# STM32G071 register map
File version: 2.1
CPU: CM0 r0p1, little endian, MPU, no FPU, 4 interrupt priority bits
Registers are 32-bit, read-write, reset 0x0 unless marked. A register's access mark holds for its fields unless they carry their own. Offsets are from the block's base; [hi:lo] are bit positions.

## TIM16 — General purpose timers
Base 0x40014400
Same registers: TIM17 0x40014800
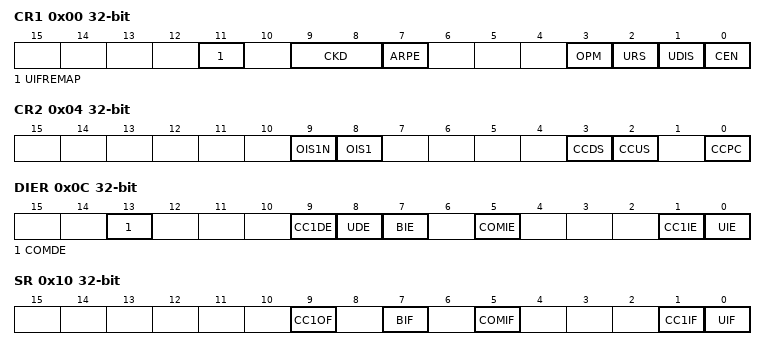
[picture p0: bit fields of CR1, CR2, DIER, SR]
0x00 CR1 — control register 1
  [11] UIFREMAP — UIF status bit remapping
  [9:8] CKD — Clock division
  [7] ARPE — Auto-reload preload enable
  [3] OPM — One-pulse mode
  [2] URS — Update request source
  [1] UDIS — Update disable
  [0] CEN — Counter enable
0x04 CR2 — control register 2
  [9] OIS1N — Output Idle state 1
  [8] OIS1 — Output Idle state 1
  [3] CCDS — Capture/compare DMA selection
  [2] CCUS — Capture/compare control update selection
  [0] CCPC — Capture/compare preloaded control
0x0C DIER — DMA/Interrupt enable register
  [13] COMDE — COM DMA request enable
  [9] CC1DE — Capture/Compare 1 DMA request enable
  [8] UDE — Update DMA request enable
  [7] BIE — Break interrupt enable
  [5] COMIE — COM interrupt enable
  [1] CC1IE — Capture/Compare 1 interrupt enable
  [0] UIE — Update interrupt enable
0x10 SR — status register
  [9] CC1OF — Capture/Compare 1 overcapture flag
  [7] BIF — Break interrupt flag
  [5] COMIF — COM interrupt flag
  [1] CC1IF — Capture/compare 1 interrupt flag
  [0] UIF — Update interrupt flag
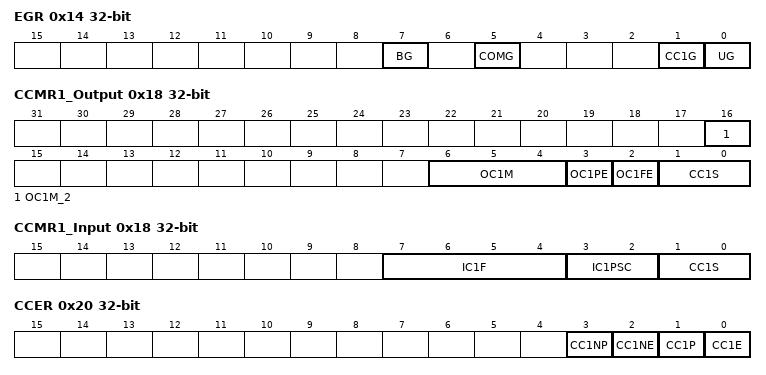
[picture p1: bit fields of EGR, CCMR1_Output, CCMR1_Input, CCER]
0x14 EGR wo — event generation register
  [7] BG — Break generation
  [5] COMG — Capture/Compare control update generation
  [1] CC1G — Capture/compare 1 generation
  [0] UG — Update generation
0x18 CCMR1_Output — capture/compare mode register (output mode)
  [16] OC1M_2 — Output Compare 1 mode
  [6:4] OC1M — Output Compare 1 mode
  [3] OC1PE — Output Compare 1 preload enable
  [2] OC1FE — Output Compare 1 fast enable
  [1:0] CC1S — Capture/Compare 1 selection
0x18 CCMR1_Input (alternate view of CCMR1_Output) — capture/compare mode register 1 (input mode)
  [7:4] IC1F — Input capture 1 filter
  [3:2] IC1PSC — Input capture 1 prescaler
  [1:0] CC1S — Capture/Compare 1 selection
0x20 CCER — capture/compare enable register
  [3] CC1NP — Capture/Compare 1 output Polarity
  [2] CC1NE — Capture/Compare 1 complementary output enable
  [1] CC1P — Capture/Compare 1 output Polarity
  [0] CC1E — Capture/Compare 1 output enable
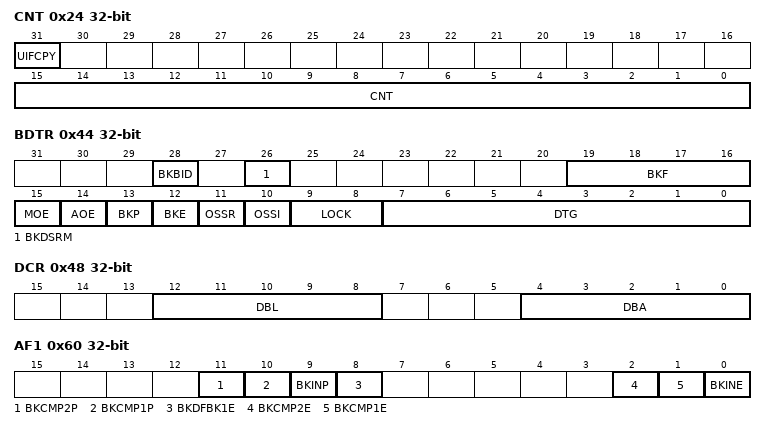
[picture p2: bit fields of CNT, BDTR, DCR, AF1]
0x24 CNT access per field — counter
  [31] UIFCPY ro — UIF Copy
  [15:0] CNT rw — counter value
0x28 PSC — prescaler
  [15:0] PSC — Prescaler value
0x2C ARR — auto-reload register
  [15:0] ARR — Auto-reload value
0x30 RCR — repetition counter register
  [7:0] REP — Repetition counter value
0x34 CCR1 — capture/compare register 1
  [15:0] CCR1 — Capture/Compare 1 value
0x44 BDTR — break and dead-time register
  [28] BKBID — Break Bidirectional
  [26] BKDSRM — Break Disarm
  [19:16] BKF — Break filter
  [15] MOE — Main output enable
  [14] AOE — Automatic output enable
  [13] BKP — Break polarity
  [12] BKE — Break enable
  [11] OSSR — Off-state selection for Run mode
  [10] OSSI — Off-state selection for Idle mode
  [9:8] LOCK — Lock configuration
  [7:0] DTG — Dead-time generator setup
0x48 DCR — DMA control register
  [12:8] DBL — DMA burst length
  [4:0] DBA — DMA base address
0x4C DMAR — DMA address for full transfer
  [15:0] DMAB — DMA register for burst accesses
0x60 AF1 — TIM17 option register 1
  [11] BKCMP2P — BRK COMP2 input polarit
  [10] BKCMP1P — BRK COMP1 input polarity
  [9] BKINP — BRK BKIN input polarity
  [8] BKDFBK1E — BRK DFSDM_BREAK1 enable
  [2] BKCMP2E — BRK COMP2 enable
  [1] BKCMP1E — BRK COMP1 enable
  [0] BKINE — BRK BKIN input enable
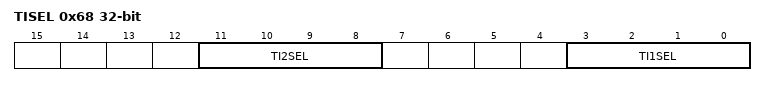
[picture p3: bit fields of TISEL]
0x68 TISEL — input selection register
  [11:8] TI2SEL — selects input
  [3:0] TI1SEL — selects input

## SPI1 — Serial peripheral interface/Inter-IC sound
Base 0x40013000
Same registers: SPI2 0x40003800
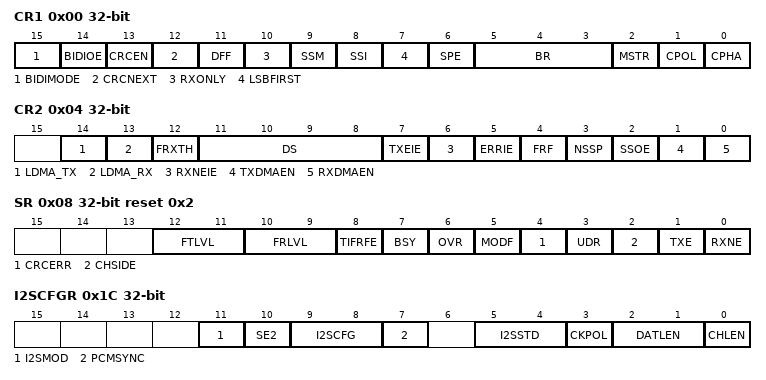
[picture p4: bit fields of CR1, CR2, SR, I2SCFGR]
0x00 CR1 — control register 1
  [15] BIDIMODE — Bidirectional data mode enable
  [14] BIDIOE — Output enable in bidirectional mode
  [13] CRCEN — Hardware CRC calculation enable
  [12] CRCNEXT — CRC transfer next
  [11] DFF — Data frame format
  [10] RXONLY — Receive only
  [9] SSM — Software slave management
  [8] SSI — Internal slave select
  [7] LSBFIRST — Frame format
  [6] SPE — SPI enable
  [5:3] BR — Baud rate control
  [2] MSTR — Master selection
  [1] CPOL — Clock polarity
  [0] CPHA — Clock phase
0x04 CR2 — control register 2
  [14] LDMA_TX — Last DMA transfer for transmission
  [13] LDMA_RX — Last DMA transfer for reception
  [12] FRXTH — FIFO reception threshold
  [11:8] DS — Data size
  [7] TXEIE — Tx buffer empty interrupt enable
  [6] RXNEIE — RX buffer not empty interrupt enable
  [5] ERRIE — Error interrupt enable
  [4] FRF — Frame format
  [3] NSSP — NSS pulse management
  [2] SSOE — SS output enable
  [1] TXDMAEN — Tx buffer DMA enable
  [0] RXDMAEN — Rx buffer DMA enable
0x08 SR access per field reset 0x2 — status register
  [12:11] FTLVL ro — FIFO transmission level
  [10:9] FRLVL ro — FIFO reception level
  [8] TIFRFE ro — TI frame format error
  [7] BSY ro — Busy flag
  [6] OVR ro — Overrun flag
  [5] MODF ro — Mode fault
  [4] CRCERR rw — CRC error flag
  [3] UDR ro — Underrun flag
  [2] CHSIDE ro — Channel side
  [1] TXE ro — Transmit buffer empty
  [0] RXNE ro — Receive buffer not empty
0x0C DR — data register
  [15:0] DR — Data register
0x10 CRCPR reset 0x7 — CRC polynomial register
  [15:0] CRCPOLY
0x14 RXCRCR ro — RX CRC register
  [15:0] RxCRC
0x18 TXCRCR ro — TX CRC register
  [15:0] TxCRC
0x1C I2SCFGR — configuration register
  [11] I2SMOD — I2S mode selection
  [10] SE2 — I2S enable
  [9:8] I2SCFG — I2S configuration mode
  [7] PCMSYNC — PCM frame synchronization
  [5:4] I2SSTD — standard selection
  [3] CKPOL — Inactive state clock polarity
  [2:1] DATLEN — Data length to be transferred
  [0] CHLEN — Channel length (number of bits per audio channel)
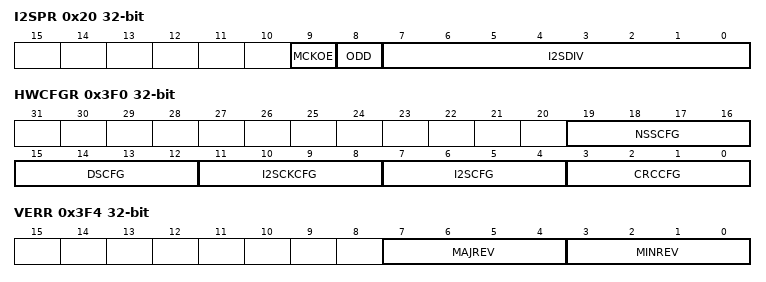
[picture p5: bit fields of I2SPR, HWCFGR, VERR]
0x20 I2SPR — prescaler register
  [9] MCKOE — Master clock output enable
  [8] ODD — Odd factor for the prescaler
  [7:0] I2SDIV — linear prescaler
0x3F0 HWCFGR ro — hardware configuration register
  [19:16] NSSCFG — NSS pulse feature enhancement at SPI master
  [15:12] DSCFG — SPI data size configuration
  [11:8] I2SCKCFG — I2S master clock generator at I2S mode
  [7:4] I2SCFG — I2S mode implementation
  [3:0] CRCCFG — CRC capable at SPI mode
0x3F4 VERR ro — EXTI IP Version register
  [7:4] MAJREV — Major Revision number
  [3:0] MINREV — Minor Revision number
0x3F8 IPIDR ro — EXTI Identification register
  [31:0] IPID — IP Identification
0x3FC SIDR ro — EXTI Size ID register
  [31:0] SID — Size Identification
